AUTOSAR XML (schema 00048)
package /ComponentTypes
  swc implementation Power_Implementation: behavior=Power_InternalBehavior
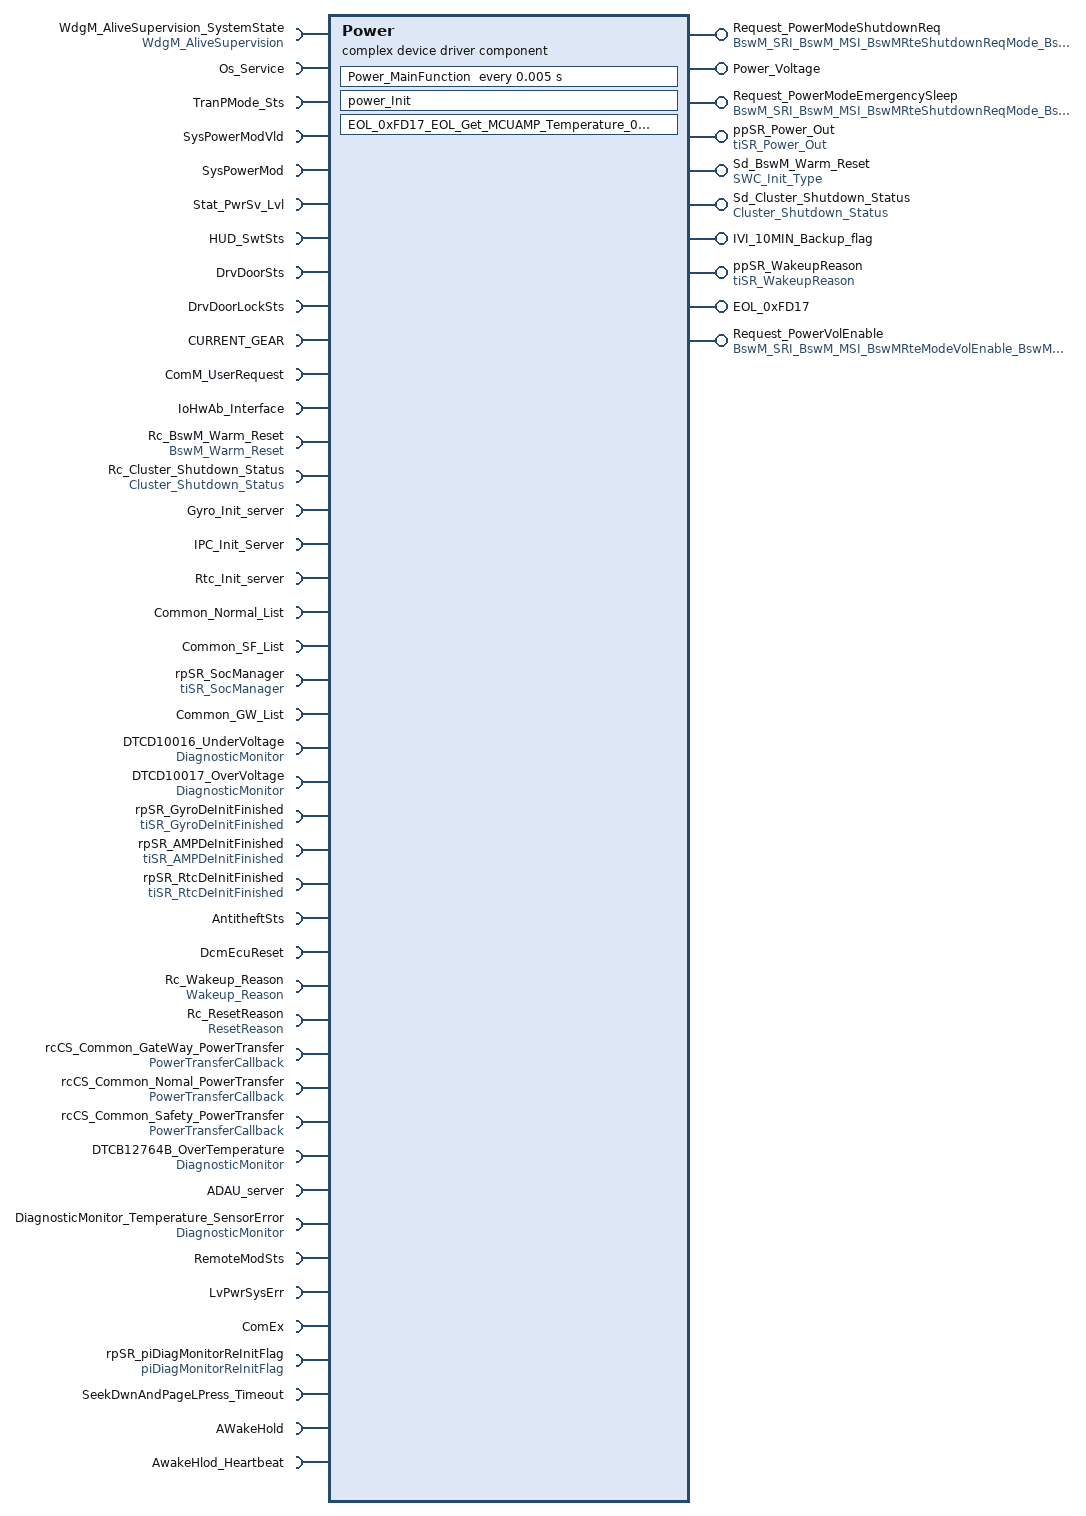
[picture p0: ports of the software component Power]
  complex device driver sw component type Power
    provide port Request_PowerModeShutdownReq: nonqueued-sender-com-spec{data-element=requestedMode, init-value=0}, provided-interface=BswM_SRI_BswM_MSI_BswMRteShutdownReqMode_BswM_MDGP_BswMRteShutdownReqMode
    provide/require port Ecum_Set_SystemState_Run: nonqueued-sender-com-spec{data-element=Element, init-value=0}, nonqueued-receiver-com-spec{data-element=Element, filter=data-filter-type=ALWAYS}, provided-required-interface=Ecum_Set_SystemState_Run
    11 x require port:
      WdgM_AliveSupervision_SystemState: client-com-spec=CheckpointReached, required-interface=WdgM_AliveSupervision
      Os_Service: required-com-specs=[GetElapsedValue, GetCounterValue], required-interface=Os_Service
      TranPMode_Sts: nonqueued-receiver-com-spec{data-element=TranPMode_Sts, alive-timeout=1, filter=data-filter-type=ALWAYS, handle-never-received=true, init-value=0}, required-interface=TranPMode_Sts
      SysPowerModVld: nonqueued-receiver-com-spec{data-element=SysPowerModVld, alive-timeout=0.5, filter=data-filter-type=ALWAYS, handle-never-received=true, init-value=0}, required-interface=SysPowerModVld
      SysPowerMod: nonqueued-receiver-com-spec{data-element=SysPowerMod, alive-timeout=0.5, filter=data-filter-type=ALWAYS, handle-never-received=true, init-value=0}, required-interface=SysPowerMod
      Stat_PwrSv_Lvl: nonqueued-receiver-com-spec{data-element=Stat_PwrSv_Lvl, alive-timeout=0.5, filter=data-filter-type=ALWAYS, handle-never-received=true, init-value=0}, required-interface=Stat_PwrSv_Lvl
      HUD_SwtSts: nonqueued-receiver-com-spec{data-element=HUD_SwtSts, alive-timeout=1, filter=data-filter-type=ALWAYS, handle-never-received=true, init-value=1}, required-interface=HUD_SwtSts
      DrvDoorSts: nonqueued-receiver-com-spec{data-element=DrvDoorSts, alive-timeout=0.5, filter=data-filter-type=ALWAYS, handle-never-received=true, init-value=0}, required-interface=DrvDoorSts
      DrvDoorLockSts: nonqueued-receiver-com-spec{data-element=DrvDoorLockSts, alive-timeout=0.5, filter=data-filter-type=ALWAYS, handle-never-received=true, init-value=0}, required-interface=DrvDoorLockSts
      CURRENT_GEAR: nonqueued-receiver-com-spec{data-element=CURRENT_GEAR, alive-timeout=0.2, filter=data-filter-type=ALWAYS, handle-never-received=true, init-value=0}, required-interface=CURRENT_GEAR
      ComM_UserRequest: required-com-specs=[GetRequestedComMode, GetMaxComMode, GetCurrentComMode, RequestComMode], required-interface=ComM_UserRequest
    provide port Power_Voltage: nonqueued-sender-com-spec{data-element=Element, init-value=fields=[state:0, value:0]}, provided-interface=Power_Voltage
    provide port Request_PowerModeEmergencySleep: nonqueued-sender-com-spec=requestedMode, provided-interface=BswM_SRI_BswM_MSI_BswMRteShutdownReqMode_BswM_MDGP_BswMRteShutdownReqMode
    require port IoHwAb_Interface: required-com-specs=[SetHsLsOutput, SetPeriodAndDuty, SetDuty, SetPin, GetPin, GetVoltage], required-interface=IoHwAb_Interface
    provide port ppSR_Power_Out: nonqueued-sender-com-spec{data-element=SystemStateOut, init-value=constant-reference=PowerOutInit}, provided-interface=tiSR_Power_Out
    require port Rc_BswM_Warm_Reset: nonqueued-receiver-com-spec{data-element=Element, filter=data-filter-type=ALWAYS, init-value=0}, required-interface=BswM_Warm_Reset
    provide port Sd_BswM_Warm_Reset: nonqueued-sender-com-spec{data-element=Element, init-value=0}, provided-interface=SWC_Init_Type
    provide port Sd_Cluster_Shutdown_Status: nonqueued-sender-com-spec{data-element=Element, init-value=0}, provided-interface=Cluster_Shutdown_Status
    6 x require port:
      Rc_Cluster_Shutdown_Status: nonqueued-receiver-com-spec{data-element=Element, filter=data-filter-type=ALWAYS, init-value=0}, required-interface=Cluster_Shutdown_Status
      Gyro_Init_server: client-com-spec=Operation, required-interface=Gyro_Init_server
      IPC_Init_Server: client-com-spec=Operation, required-interface=IPC_Init_Server
      Rtc_Init_server: client-com-spec=Operation, required-interface=Rtc_Init_server
      Common_Normal_List: required-com-specs=[Deinit, Int], required-interface=Common_Normal_List
      Common_SF_List: required-com-specs=[Deinit, Int], required-interface=Common_SF_List
    provide port IVI_10MIN_Backup_flag: nonqueued-sender-com-spec{data-element=Element, init-value=0}, provided-interface=IVI_10MIN_Backup_flag
    11 x require port:
      rpSR_SocManager: nonqueued-receiver-com-spec{data-element=SystemState, filter=data-filter-type=ALWAYS, init-value=0}, required-interface=tiSR_SocManager
      Common_GW_List: required-com-specs=[Deinit, Int], required-interface=Common_GW_List
      DTCD10016_UnderVoltage: required-interface=DiagnosticMonitor
        required-com-specs:
          GetEventExtendedDataRecordEx
          GetEventFreezeFrameDataEx
          GetFaultDetectionCounter
          GetDTCOfEvent
          GetEventTested
          GetEventFailed
          GetEventStatus
          GetEventUdsStatus
          ResetEventDebounceStatus
          ResetEventStatus
          SetEventStatus
      DTCD10017_OverVoltage: required-interface=DiagnosticMonitor
        required-com-specs:
          GetEventExtendedDataRecordEx
          GetEventFreezeFrameDataEx
          GetFaultDetectionCounter
          GetDTCOfEvent
          GetEventTested
          GetEventFailed
          GetEventStatus
          GetEventUdsStatus
          ResetEventDebounceStatus
          ResetEventStatus
          SetEventStatus
      rpSR_GyroDeInitFinished: nonqueued-receiver-com-spec{data-element=State, filter=data-filter-type=ALWAYS, init-value=0}, required-interface=tiSR_GyroDeInitFinished
      rpSR_AMPDeInitFinished: nonqueued-receiver-com-spec{data-element=State, filter=data-filter-type=ALWAYS, init-value=0}, required-interface=tiSR_AMPDeInitFinished
      rpSR_RtcDeInitFinished: nonqueued-receiver-com-spec{data-element=State, filter=data-filter-type=ALWAYS, init-value=0}, required-interface=tiSR_RtcDeInitFinished
      AntitheftSts: nonqueued-receiver-com-spec{data-element=AntitheftSts, alive-timeout=0.5, filter=data-filter-type=ALWAYS, handle-never-received=true, init-value=0}, required-interface=AntitheftSts
      DcmEcuReset: mode-switch-receiver-com-spec=DcmEcuReset, required-interface=DcmEcuReset
      Rc_Wakeup_Reason: nonqueued-receiver-com-spec{data-element=WakeupSource, filter=data-filter-type=ALWAYS, init-value=0}, required-interface=Wakeup_Reason
      Rc_ResetReason: nonqueued-receiver-com-spec{data-element=ResetSource, filter=data-filter-type=ALWAYS, init-value=0}, required-interface=ResetReason
    provide port ppSR_WakeupReason: nonqueued-sender-com-spec{data-element=data, init-value=0}, provided-interface=tiSR_WakeupReason
    provide port EOL_0xFD17: server-com-spec{operation=EOL_Get_MCUAMP_Temperature_0xFD17, queue-length=1}, provided-interface=EOL_0xFD17
    11 x require port:
      rcCS_Common_GateWay_PowerTransfer: required-com-specs=[Nomal2StandbyCallback, Standby2NomalCallback], required-interface=PowerTransferCallback
      rcCS_Common_Nomal_PowerTransfer: required-com-specs=[Nomal2StandbyCallback, Standby2NomalCallback], required-interface=PowerTransferCallback
      rcCS_Common_Safety_PowerTransfer: required-com-specs=[Nomal2StandbyCallback, Standby2NomalCallback], required-interface=PowerTransferCallback
      DTCB12764B_OverTemperature: required-interface=DiagnosticMonitor
        required-com-specs:
          GetEventExtendedDataRecordEx
          GetEventFreezeFrameDataEx
          GetFaultDetectionCounter
          GetDTCOfEvent
          GetEventTested
          GetEventFailed
          GetEventStatus
          GetEventUdsStatus
          ResetEventDebounceStatus
          ResetEventStatus
          SetEventStatus
      ADAU_server: required-com-specs=[StateToDeInit, StateToInit], required-interface=ADAU_server
      DiagnosticMonitor_Temperature_SensorError: required-interface=DiagnosticMonitor
        required-com-specs:
          GetEventExtendedDataRecordEx
          GetEventFreezeFrameDataEx
          GetFaultDetectionCounter
          GetDTCOfEvent
          GetEventTested
          GetEventFailed
          GetEventStatus
          GetEventUdsStatus
          ResetEventDebounceStatus
          ResetEventStatus
          SetEventStatus
      RemoteModSts: nonqueued-receiver-com-spec{data-element=RemoteModSts, alive-timeout=1, filter=data-filter-type=ALWAYS, handle-never-received=true, init-value=0}, required-interface=RemoteModSts
      LvPwrSysErr: nonqueued-receiver-com-spec{data-element=LvPwrSysErr, alive-timeout=0.5, filter=data-filter-type=ALWAYS, handle-never-received=true, init-value=0}, required-interface=LvPwrSysErr
      ComEx: required-com-specs=[SendSignal, ReceiveSignal, GetRxE2EStatus], required-interface=ComEx
      rpSR_piDiagMonitorReInitFlag: nonqueued-receiver-com-spec{data-element=ChangeCounter, filter=data-filter-type=ALWAYS, init-value=0}, required-interface=piDiagMonitorReInitFlag
      SeekDwnAndPageLPress_Timeout: nonqueued-receiver-com-spec{data-element=Element, filter=data-filter-type=ALWAYS, init-value=0}, required-interface=SeekDwnAndPageLPress_Timeout
    provide port Request_PowerVolEnable: nonqueued-sender-com-spec=requestedMode, provided-interface=BswM_SRI_BswM_MSI_BswMRteModeVolEnable_BswM_MDGP_BswMRteModeVolEnable
    require port AWakeHold: nonqueued-receiver-com-spec{data-element=DVRRemtCnSts, filter=data-filter-type=ALWAYS, init-value=0}, required-interface=AWakeHold
    require port AwakeHlod_Heartbeat: nonqueued-receiver-com-spec{data-element=counter, filter=data-filter-type=ALWAYS, init-value=0}, required-interface=AwakeHlod_Heartbeat
    behavior Power_InternalBehavior
      timing event TMT_SystemState_MainFunction: start-on-event=Power_MainFunction, period=0.005
      init event SystemState_InitEvent: start-on-event=power_Init
      operation invoked event OIT_EOL_0xFD17_EOL_Get_MCUAMP_Temperature_0xFD17_EOL_0xFD17_EOL_Get_MCUAMP_Temperature_0xFD17: start-on-event=EOL_0xFD17_EOL_Get_MCUAMP_Temperature_0xFD17, operation=EOL_0xFD17.EOL_Get_MCUAMP_Temperature_0xFD17
      port-api-options:
        enable-take-address=true, error-handling=NO-TRANSFORMER-ERROR-HANDLING, indirect-api=false, port=Gyro_Init_server
        enable-take-address=true, error-handling=NO-TRANSFORMER-ERROR-HANDLING, indirect-api=false, port=IPC_Init_Server
        enable-take-address=true, error-handling=NO-TRANSFORMER-ERROR-HANDLING, indirect-api=false, port=Rtc_Init_server
        enable-take-address=true, error-handling=NO-TRANSFORMER-ERROR-HANDLING, indirect-api=false, port=Common_GW_List
        enable-take-address=true, error-handling=NO-TRANSFORMER-ERROR-HANDLING, indirect-api=false, port=Common_Normal_List
        enable-take-address=true, error-handling=NO-TRANSFORMER-ERROR-HANDLING, indirect-api=false, port=Common_SF_List
        enable-take-address=true, error-handling=NO-TRANSFORMER-ERROR-HANDLING, indirect-api=false, port=rcCS_Common_GateWay_PowerTransfer
        enable-take-address=true, error-handling=NO-TRANSFORMER-ERROR-HANDLING, indirect-api=false, port=rcCS_Common_Nomal_PowerTransfer
        enable-take-address=true, error-handling=NO-TRANSFORMER-ERROR-HANDLING, indirect-api=false, port=rcCS_Common_Safety_PowerTransfer
        enable-take-address=true, error-handling=NO-TRANSFORMER-ERROR-HANDLING, indirect-api=false, port=ADAU_server
      runnable Power_MainFunction: mode-access-point=DcmEcuReset.DcmEcuReset
        data-receive-point-by-arguments:
          24 x access:
            REC_Ecum_Set_SystemState_Run_Element: accessed-variable=Ecum_Set_SystemState_Run.Element
            REC_CURRENT_GEAR_CURRENT_GEAR: accessed-variable=CURRENT_GEAR.CURRENT_GEAR
            REC_DrvDoorLockSts_DrvDoorLockSts: accessed-variable=DrvDoorLockSts.DrvDoorLockSts
            REC_DrvDoorSts_DrvDoorSts: accessed-variable=DrvDoorSts.DrvDoorSts
            REC_HUD_SwtSts_HUD_SwtSts: accessed-variable=HUD_SwtSts.HUD_SwtSts
            REC_LvPwrSysErr_LvPwrSysErr: accessed-variable=LvPwrSysErr.LvPwrSysErr
            REC_Stat_PwrSv_Lvl_Stat_PwrSv_Lvl: accessed-variable=Stat_PwrSv_Lvl.Stat_PwrSv_Lvl
            REC_SysPowerMod_SysPowerMod: accessed-variable=SysPowerMod.SysPowerMod
            REC_SysPowerModVld_SysPowerModVld: accessed-variable=SysPowerModVld.SysPowerModVld
            REC_TranPMode_Sts_TranPMode_Sts: accessed-variable=TranPMode_Sts.TranPMode_Sts
            REC_BswM_Warm_Reset_Element: accessed-variable=Rc_BswM_Warm_Reset.Element
            REC_Rc_Cluster_Shutdown_Status_Element: accessed-variable=Rc_Cluster_Shutdown_Status.Element
            REC_rpSR_SocManager_SystemState: accessed-variable=rpSR_SocManager.SystemState
            REC_rpSR_AMPDeInitFinished_State: accessed-variable=rpSR_AMPDeInitFinished.State
            REC_rpSR_GyroDeInitFinished_State: accessed-variable=rpSR_GyroDeInitFinished.State
            REC_rpSR_RtcDeInitFinished_State: accessed-variable=rpSR_RtcDeInitFinished.State
            REC_AntitheftSts_AntitheftSts: accessed-variable=AntitheftSts.AntitheftSts
            REC_Rc_ResetReason_ResetSource: accessed-variable=Rc_ResetReason.ResetSource
            REC_Rc_Wakeup_Reason_WakeupSource: accessed-variable=Rc_Wakeup_Reason.WakeupSource
            REC_RemoteModSts_RemoteModSts: accessed-variable=RemoteModSts.RemoteModSts
            REC_rpSR_piDiagMonitorReInitFlag_ChangeCounter: accessed-variable=rpSR_piDiagMonitorReInitFlag.ChangeCounter
            REC_SeekDwnAndPageLPress_Timeout_Element: accessed-variable=SeekDwnAndPageLPress_Timeout.Element
            REC_AWakeHold_DVRRemtCnSts: accessed-variable=AWakeHold.DVRRemtCnSts
            REC_AwakeHlod_Heartbeat_counter: accessed-variable=AwakeHlod_Heartbeat.counter
        data-send-points:
          10 x access:
            SEND_Request_PowerModeShutdownReq_requestedMode: accessed-variable=Request_PowerModeShutdownReq.requestedMode
            SEND_Ecum_Set_SystemState_Run_Element: accessed-variable=Ecum_Set_SystemState_Run.Element
            SEND_Request_PowerModeEmergencySleep_requestedMode: accessed-variable=Request_PowerModeEmergencySleep.requestedMode
            SEND_ppSR_Power_Out_SystemStateOut: accessed-variable=ppSR_Power_Out.SystemStateOut
            SEND_Sd_Cluster_Shutdown_Status_Element: accessed-variable=Sd_Cluster_Shutdown_Status.Element
            SEND_IVI_10MIN_Backup_flag_Element: accessed-variable=IVI_10MIN_Backup_flag.Element
            SEND_ppSR_WakeupReason_data: accessed-variable=ppSR_WakeupReason.data
            SEND_Power_Voltage_Element: accessed-variable=Power_Voltage.Element
            SEND_Sd_BswM_Warm_Reset_Element: accessed-variable=Sd_BswM_Warm_Reset.Element
            SEND_Request_PowerVolEnable_requestedMode: accessed-variable=Request_PowerVolEnable.requestedMode
        35 x sync call:
          SC_WdgM_AliveSupervision_SystemState_CheckpointReached: operation=WdgM_AliveSupervision_SystemState.CheckpointReached
          SC_Os_Service_GetCounterValue: operation=Os_Service.GetCounterValue
          SC_Os_Service_GetElapsedValue: operation=Os_Service.GetElapsedValue
          SC_ComM_UserRequest_GetCurrentComMode: operation=ComM_UserRequest.GetCurrentComMode
          SC_ComM_UserRequest_GetMaxComMode: operation=ComM_UserRequest.GetMaxComMode
          SC_ComM_UserRequest_GetRequestedComMode: operation=ComM_UserRequest.GetRequestedComMode
          SC_ComM_UserRequest_RequestComMode: operation=ComM_UserRequest.RequestComMode
          SC_IoHwAb_Interface_GetVoltage: operation=IoHwAb_Interface.GetVoltage
          SC_Gyro_Init_server_Operation: operation=Gyro_Init_server.Operation
          SC_IPC_Init_Server_Operation: operation=IPC_Init_Server.Operation
          SC_Rtc_Init_server_Operation: operation=Rtc_Init_server.Operation
          SC_Common_GW_List_Deinit: operation=Common_GW_List.Deinit
          SC_Common_GW_List_Int: operation=Common_GW_List.Int
          SC_Common_Normal_List_Deinit: operation=Common_Normal_List.Deinit
          SC_Common_Normal_List_Int: operation=Common_Normal_List.Int
          SC_Common_SF_List_Deinit: operation=Common_SF_List.Deinit
          SC_Common_SF_List_Int: operation=Common_SF_List.Int
          SC_DTCD10016_UnderVoltage_ResetEventStatus: operation=DTCD10016_UnderVoltage.ResetEventStatus
          SC_DTCD10017_OverVoltage_ResetEventStatus: operation=DTCD10017_OverVoltage.ResetEventStatus
          SC_DTCD10016_UnderVoltage_SetEventStatus: operation=DTCD10016_UnderVoltage.SetEventStatus
          SC_DTCD10017_OverVoltage_SetEventStatus: operation=DTCD10017_OverVoltage.SetEventStatus
          SC_rcCS_Common_GateWay_PowerTransfer_Nomal2StandbyCallback: operation=rcCS_Common_GateWay_PowerTransfer.Nomal2StandbyCallback
          SC_rcCS_Common_GateWay_PowerTransfer_Standby2NomalCallback: operation=rcCS_Common_GateWay_PowerTransfer.Standby2NomalCallback
          SC_rcCS_Common_Nomal_PowerTransfer_Nomal2StandbyCallback: operation=rcCS_Common_Nomal_PowerTransfer.Nomal2StandbyCallback
          SC_rcCS_Common_Nomal_PowerTransfer_Standby2NomalCallback: operation=rcCS_Common_Nomal_PowerTransfer.Standby2NomalCallback
          SC_rcCS_Common_Safety_PowerTransfer_Nomal2StandbyCallback: operation=rcCS_Common_Safety_PowerTransfer.Nomal2StandbyCallback
          SC_rcCS_Common_Safety_PowerTransfer_Standby2NomalCallback: operation=rcCS_Common_Safety_PowerTransfer.Standby2NomalCallback
          SC_DTCB12764B_OverTemperature_ResetEventStatus: operation=DTCB12764B_OverTemperature.ResetEventStatus
          SC_DTCB12764B_OverTemperature_SetEventStatus: operation=DTCB12764B_OverTemperature.SetEventStatus
          SC_ADAU_server_StateToDeInit: operation=ADAU_server.StateToDeInit
          SC_ADAU_server_StateToInit: operation=ADAU_server.StateToInit
          SC_DiagnosticMonitor_Temperature_SensorError_SetEventStatus: operation=DiagnosticMonitor_Temperature_SensorError.SetEventStatus
          SC_ComEx_GetRxE2EStatus: operation=ComEx.GetRxE2EStatus
          SC_ComEx_ReceiveSignal: operation=ComEx.ReceiveSignal
          SC_ComEx_SendSignal: operation=ComEx.SendSignal
      runnable power_Init
      runnable EOL_0xFD17_EOL_Get_MCUAMP_Temperature_0xFD17
